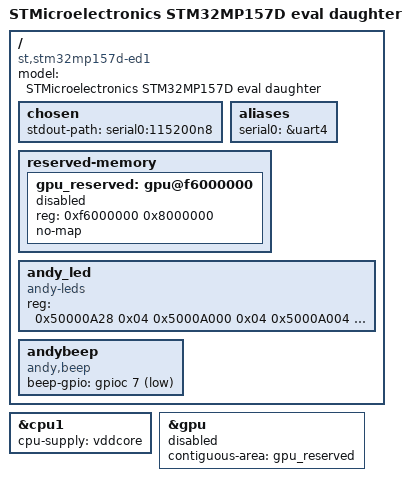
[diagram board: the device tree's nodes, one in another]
// SPDX-License-Identifier: (GPL-2.0+ OR BSD-3-Clause)
/*
 * Copyright (C) STMicroelectronics 2019 - All Rights Reserved
 * Author: Alexandre Torgue <alexandre.torgue@st.com> for STMicroelectronics.
 */
/dts-v1/;

#include "stm32mp157.dtsi"
#include "stm32mp15xd.dtsi"
#include "stm32mp15-pinctrl.dtsi"
#include "stm32mp15xxaa-pinctrl.dtsi"
#include "stm32mp157-m4-srm.dtsi"
#include "stm32mp157-m4-srm-pinctrl.dtsi"
#include "stm32mp157d-andy.dtsi"

/ {
	model = "STMicroelectronics STM32MP157D eval daughter";
	compatible = "st,stm32mp157d-ed1", "st,stm32mp157";

	chosen {
		stdout-path = "serial0:115200n8";
	};

	aliases {
		serial0 = &uart4;
	};

	reserved-memory {
		gpu_reserved: gpu@f6000000 {
			reg = <0xf6000000 0x8000000>;
			no-map;
			status = "disabled";
		};
	};
	
	andy_led {
		compatible = "andy-leds";
		status = "okay";
		reg = <0x50000A28 0x04 /* RCC_MP_AHB4ENSETR*/
			0x5000A000 0x04 /* GPIOI_MODER*/
			0x5000A004 0x04 /* GPIOI_OTYPER*/
			0x5000A008 0x04 /* GPIOI_OSPEEDR*/
			0x5000A00C 0x04 /* GPIOI_PUPDR*/
			0x5000A018 0x04 /* GPIOI_BSRR*/
		>;
	};
	
	andybeep {
		compatible = "andy,beep";
		status = "okay";
		/*
		 * BEEP is driven by PC7 through a 1K base resistor into the
		 * S8550 PNP transistor Q1 (base pulled to VCC3.3 by R108).
		 * Pulling PC7 low turns Q1 on and sounds the buzzer, so the
		 * GPIO is active low.
		 */
		beep-gpio = <&gpioc 7 GPIO_ACTIVE_LOW>;
	};
};

&cpu1{
	cpu-supply = <&vddcore>;
};

&gpu {
	contiguous-area = <&gpu_reserved>;
	status = "disabled";
};
